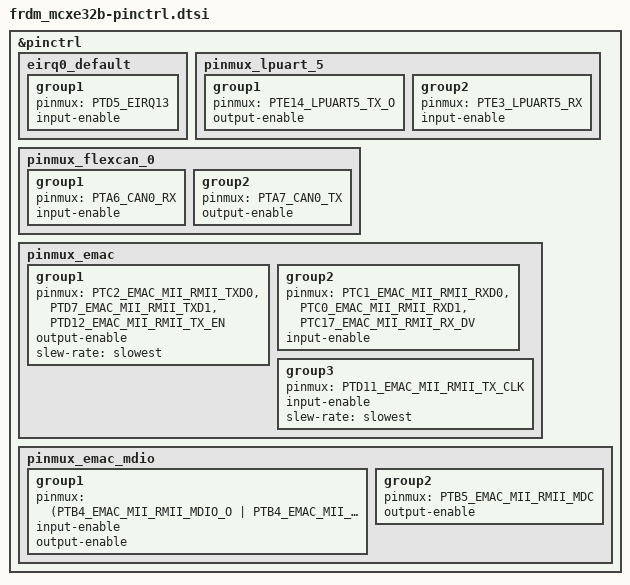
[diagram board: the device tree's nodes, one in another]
/*
 * SPDX-FileCopyrightText: Copyright 2026 NXP
 *
 * SPDX-License-Identifier: Apache-2.0
 */

#include <nxp/mcx/mcxe/pinctrl/MCXE32BMPB-pinctrl.h>

&pinctrl {
	eirq0_default: eirq0_default {
		group1 {
			pinmux = <PTD5_EIRQ13>;
			input-enable;
		};
	};

	pinmux_lpuart_5: pinmux_lpuart_5 {
		group1 {
			pinmux = <PTE14_LPUART5_TX_O>;
			output-enable;
		};

		group2 {
			pinmux = <PTE3_LPUART5_RX>;
			input-enable;
		};
	};

	pinmux_flexcan_0: pinmux_flexcan_0 {
		group1 {
			pinmux = <PTA6_CAN0_RX>;
			input-enable;
		};

		group2 {
			pinmux = <PTA7_CAN0_TX>;
			output-enable;
		};
	};

	pinmux_emac: pinmux_emac {
		group1 {
			/*
			 * RMII outputs. The slowest slew rate matches the NXP
			 * reference pin configuration for this board.
			 */
			pinmux = <PTC2_EMAC_MII_RMII_TXD0>,
				 <PTD7_EMAC_MII_RMII_TXD1>,
				 <PTD12_EMAC_MII_RMII_TX_EN>;
			output-enable;
			slew-rate = "slowest";
		};

		group2 {
			pinmux = <PTC1_EMAC_MII_RMII_RXD0>,
				 <PTC0_EMAC_MII_RMII_RXD1>,
				 <PTC17_EMAC_MII_RMII_RX_DV>;
			input-enable;
		};

		group3 {
			/* 50 MHz RMII reference clock supplied by the PHY */
			pinmux = <PTD11_EMAC_MII_RMII_TX_CLK>;
			input-enable;
			slew-rate = "slowest";
		};
	};

	pinmux_emac_mdio: pinmux_emac_mdio {
		group1 {
			pinmux = <(PTB4_EMAC_MII_RMII_MDIO_O | PTB4_EMAC_MII_RMII_MDIO_I)>;
			input-enable;
			output-enable;
		};

		group2 {
			pinmux = <PTB5_EMAC_MII_RMII_MDC>;
			output-enable;
		};
	};
};
